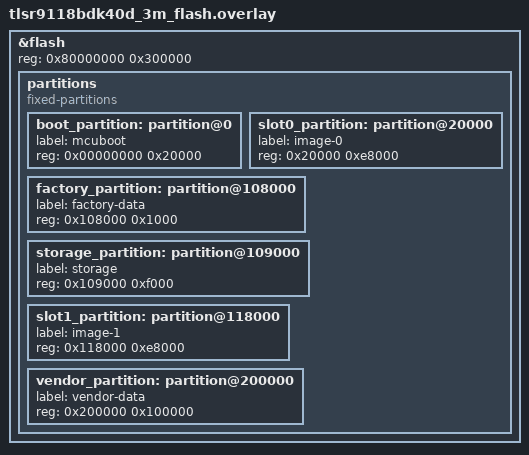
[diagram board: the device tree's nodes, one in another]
&flash {
	reg = <0x80000000 0x300000>;

	/delete-node/ partitions;
	partitions {
		compatible = "fixed-partitions";
		#address-cells = <1>;
		#size-cells = <1>;

		boot_partition: partition@0 {
			label = "mcuboot";
			reg = <0x00000000 0x20000>;
		};
		slot0_partition: partition@20000 {
			label = "image-0";
			reg = <0x20000 0xe8000>;
		};
		factory_partition: partition@108000 {
			label = "factory-data";
			reg = <0x108000 0x1000>;
		};
		storage_partition: partition@109000 {
			label = "storage";
			reg = <0x109000 0xf000>;
		};
		slot1_partition: partition@118000 {
			label = "image-1";
			reg = <0x118000 0xe8000>;
		};
		vendor_partition: partition@200000 {
			label = "vendor-data";
			reg = <0x200000 0x100000>;
		};
	};
};
